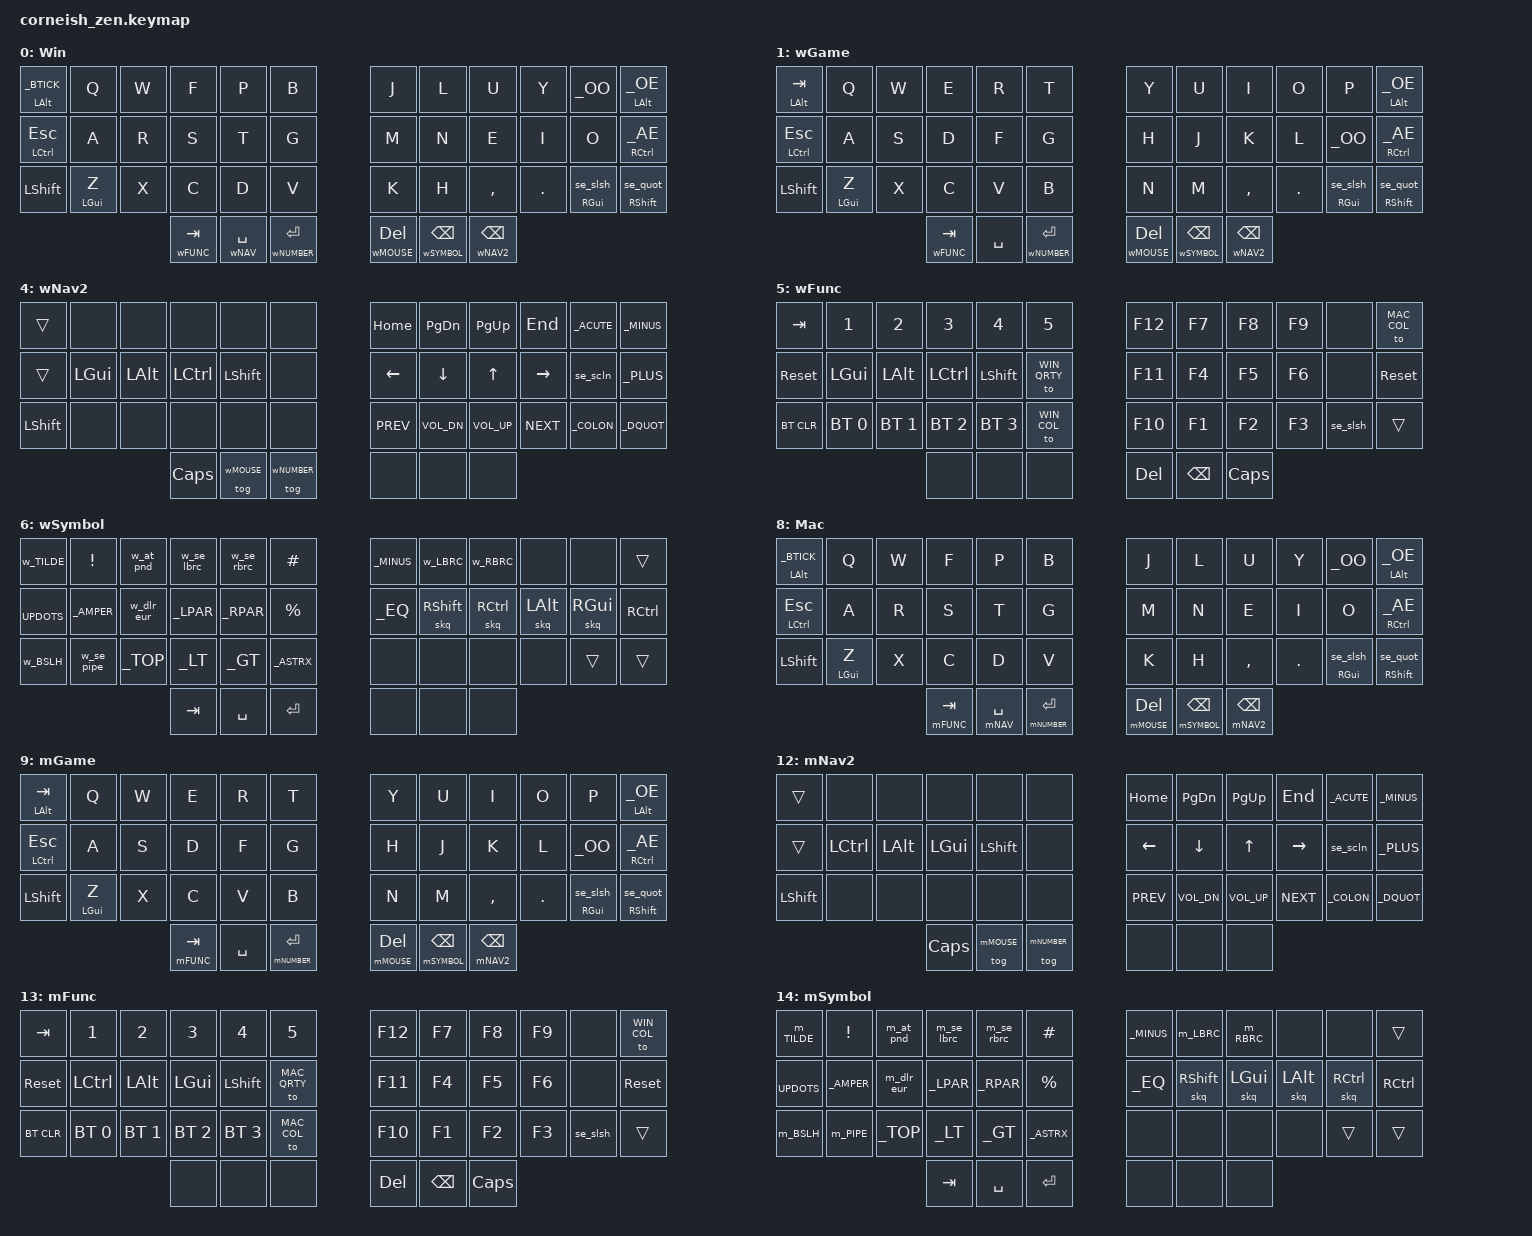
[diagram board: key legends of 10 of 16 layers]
#include <behaviors.dtsi>
#include <dt-bindings/zmk/keys.h>
#include <dt-bindings/zmk/bt.h>

// Override default movement and scrolling max velocities
#define ZMK_POINTING_DEFAULT_MOVE_VAL 1500  // default: 600
#define ZMK_POINTING_DEFAULT_SCRL_VAL 20    // default: 10
#include <dt-bindings/zmk/pointing.h>

// Layers for Windows
#define WIN_COL   0
#define WIN_QRTY  1
#define wNUMBER   2
#define wNAV      3
#define wNAV2     4
#define wFUNC     5
#define wSYMBOL   6
#define wMOUSE    7

// Layers for Mac
#define MAC_COL   8
#define MAC_QRTY  9
#define mNUMBER  10
#define mNAV     11
#define mNAV2    12
#define mFUNC    13
#define mSYMBOL  14
#define mMOUSE   15

// Home row mods macros for Windows
#define wHRML1(k1,k2) &l_ht LC(LGUI) k1   &l_ht LS(LALT) k2
#define wHRML2(k1,k2,k3,k4,k5,k6) &l_ht LCTRL k1   &l_ht LGUI k2   &l_ht LALT k3   &l_ht LCTRL k4   &l_ht LSHIFT k5   &l_ht LC(LS(LALT)) k6
#define wHRML3(k1,k2,k3,k4) &l_ht LA(LGUI) k1   &l_ht LC(LALT) k2   &l_ht LS(LCTRL) k3   &l_ht LC(LS(LA(LGUI))) k4

#define wHRMR1(k1,k2) &r_ht RS(RALT) k1   &r_ht RC(RGUI) k2
#define wHRMR2(k1,k2,k3,k4) &r_ht RC(RS(RALT)) k1   &r_ht RSHIFT k2   &r_ht RCTRL k3   &r_ht LALT k4
#define wHRMR3(k1,k2,k3,k4) &r_ht RC(RS(RA(RGUI))) k1   &r_ht RS(RCTRL) k2   &r_ht RC(RALT) k3   &r_ht RA(RGUI) k4

// Home row mods macros for Mac
#define mHRML1(k1,k2) &l_ht LC(LGUI) k1   &l_ht LS(LALT) k2
#define mHRML2(k1,k2,k3,k4,k5,k6) &l_ht LGUI k1   &l_ht LCTRL k2   &l_ht LALT k3   &l_ht LGUI k4   &l_ht LSHIFT k5   &l_ht LC(LS(LALT)) k6
#define mHRML3(k1,k2,k3,k4) &l_ht LA(LCTRL) k1   &l_ht LG(LALT) k2   &l_ht LS(LGUI) k3   &l_ht LC(LS(LA(LGUI))) k4

#define mHRMR1(k1,k2) &r_ht RS(RALT) k1   &r_ht RC(RGUI) k2
#define mHRMR2(k1,k2,k3,k4) &r_ht RC(RS(RALT)) k1   &r_ht RSHIFT k2   &r_ht RGUI k3   &r_ht LALT k4
#define mHRMR3(k1,k2,k3,k4) &r_ht RC(RS(RA(RGUI))) k1   &r_ht RS(RGUI) k2   &r_ht RG(RALT) k3   &r_ht RA(RCTRL) k4

// Short commands macros for Windows
#define wSHRT1(k1,k2,k3) &kp LC(k1)   &kp LC(k2)   &kp LA(LC(k3))
#define wSHRT2(k1,k2,k3,k4,k5) &l_ht LCTRL LC(k1)   &l_ht LALT LC(k2)   &l_ht LGUI LC(k3)   &l_ht LSHIFT LC(k4)   &kp LC(k5)
#define wSHRT3(k1,k2,k3,k4,k5) &kp LC(k1)   &kp LC(k2)   &kp LC(k3)   &kp LC(k4)   &kp LC(k5)

// Short commands macros for Mac
#define mSHRT1(k1,k2,k3) &kp LG(k1)   &kp LG(k2)   &kp LA(LG(k3))
#define mSHRT2(k1,k2,k3,k4,k5) &l_ht LCTRL LG(k1)   &l_ht LALT LG(k2)   &l_ht LGUI LG(k3)   &l_ht LSHIFT LG(k4)   &kp LG(k5)
#define mSHRT3(k1,k2,k3,k4,k5) &kp LG(k1)   &kp LG(k2)   &kp LG(k3)   &kp LG(k4)   &kp LG(k5)

// Special Swedish character macro for Windows and Mac
#define _OE    LBKT                /* Å */
#define _AE    SQT                 /* Ä */
#define _OO    SEMI                /* Ö */
#define _AMPER CARET               /* & */
#define w_BSLH  RC(RA(MINUS))      /* \ Windows */
#define m_BSLH  LS(RA(N7))         /* \ Mac */
#define _LT    NON_US_BSLH         /* < */
#define _GT    LS(NON_US_BSLH)     /* > */
#define _ASTRX LS(NON_US_HASH)     /* * */
#define _UPDOTS RBKT               /* ¨ */
#define w_TILDE RC(RA(RBKT))       /* ~ Windows */
#define m_TILDE RA(RBKT)           /* ~ Mac */
#define _LPAR  LS(N8)              /* ( */
#define _RPAR  LS(N9)              /* ) */
#define _TOP   RBRC                /* ^ */
#define _EQ    RPAR                /* = */
#define _UNDER LS(FSLH)            /* _ */
#define _MINUS FSLH                /* - */
#define _PLUS  MINUS               /* + */
#define _SQUOT NON_US_HASH         /* ' */
#define _DQUOT LS(N2)              /* " */
#define _SEMIC LS(COMMA)           /* ; */
#define _COLON LS(DOT)             /* : */
#define _FSLH  KP_DIVIDE           /* / */
#define _QMARK LS(MINUS)           /* ? */
#define w_LBKT  RC(RA(N8))         /* [ Windows */
#define m_LBKT  RA(N8)             /* [ Mac */
#define w_LBRC  RC(RA(N7))         /* { Windows */
#define m_LBRC  LS(RA(N8))         /* { Mac */
#define w_RBKT  RC(RA(N9))         /* ] Windows */
#define m_RBKT  RA(N9)             /* ] Mac */
#define w_RBRC  RC(RA(N0))         /* } Windows */
#define m_RBRC  LS(RA(N9))         /* } Mac */
#define w_PIPE  RC(RA(NUBS))       /* | Windows */
#define m_PIPE  RA(N7)             /* | Mac */
#define w_AT    RC(RA(N2))         /* @ Windows */
#define m_AT    RA(N2)             /* @ Mac */
#define w_DOLAR RC(RA(N4))         /* $ Windows */
#define m_DOLAR RA(N4)             /* $ Mac */
#define w_EURO  RC(RA(N5))         /* € Windows */
#define m_EURO  LS(N4)             /* € Mac */
#define w_POUND RC(RA(N3))         /* £ Windows */
#define m_POUND RA(N3)             /* £ Mac */
#define w_MICRO RC(RA(M))          /* µ Windows*/ 
#define m_MICRO RA(Y)              /* µ Mac*/ 
#define _PARGH GRAVE               /* § */
#define _HALF  LS(GRAVE)           /* ½  Windows, ° Mac*/
#define _ACUTE EQUAL               /* ´ */
#define _BTICK LS(EQUAL)           /* ` */

&mmv {
    // x-input-code = <INPUT_REL_X>;
    // y-input-code = <INPUT_REL_Y>;
    time-to-max-speed-ms = <300>;
    acceleration-exponent = <1>;
};


&msc {
    // x-input-code = <INPUT_REL_HWHEEL>;
    // y-input-code = <INPUT_REL_WHEEL>;
    time-to-max-speed-ms = <300>;
    acceleration-exponent = <1>;
};

/ {
     chosen {
          zmk,matrix_transform = &default_transform;
          //zmk,matrix_transform = &five_column_transform;
     };
};

/ {
     behaviors {
          r_ht: right_hold_tap {
               compatible = "zmk,behavior-hold-tap";
               #binding-cells = <2>;
               flavor = "tap-preferred";
               tapping-term-ms = <175>;
               quick-tap-ms = <200>;
               require-prior-idle-ms = <125>;
               bindings = <&kp>, <&kp>;
               hold-trigger-key-positions = <
                    0  1  2  3  4  5 
                   12 13 14 15 16 17
                   24 25 26 27 28 29
                   36 37 38
               >;
          };
          l_ht: left_hold_tap {
               compatible = "zmk,behavior-hold-tap";
               #binding-cells = <2>;
               flavor = "tap-preferred";
               tapping-term-ms = <175>;
               quick-tap-ms = <200>;
               require-prior-idle-ms = <125>;
               bindings = <&kp>, <&kp>;
               hold-trigger-key-positions = <
                    6  7  8  9 10 11
                   18 19 20 21 22 23
                   30 31 32 33 34 35
                38 39 40 41
               >;
          };
          // modifify toggle for left hand behavior
          ht_tog: mod_tog {
               compatible = "zmk,behavior-hold-tap";
               label = "MOD_TOG";
               #binding-cells = <2>;
               flavor = "tap-preferred";
               tapping-term-ms = <175>;
               quick-tap-ms = <200>;
               require-prior-idle-ms = <125>;
               bindings = <&kp>, <&tog>;
               hold-trigger-key-positions = <
                     6  7  8  9 10 11
                    18 19 20 21 22 23
                    30 31 32 33 34 35
                 38 39 40 41
               >;
          };
          skq: sticky_key_quick_release {
               compatible = "zmk,behavior-sticky-key";
               #binding-cells = <1>;
               bindings = <&kp>;
               release-after-ms = <5000>;
               quick-release; // deactivate the sticky key on the next key being pressed, as opposed to released
               ignore-modifiers; // ensures sticky key modifier will get combined in chain, callum-style mods 
          };
          r_quot: right_side_quote {
               compatible = "zmk,behavior-hold-tap";
               #binding-cells = <2>;
               flavor = "tap-preferred";
               tapping-term-ms = <175>;
               quick-tap-ms = <200>;
               require-prior-idle-ms = <125>; 
               bindings = <&kp>, <&se_quot>; /* necessary special case because _DQUOT is alias for LS(N2) */
               hold-trigger-key-positions = <
                    0  1  2  3  4  5 
                   12 13 14 15 16 17
                   24 25 26 27 28 29
                   36 37 38
               >;
          };
          se_quot: single_quote_shift_double_quote {            
               compatible = "zmk,behavior-mod-morph";            
               #binding-cells = <0>;
               bindings = <&kp _SQUOT>, <&kp _DQUOT>; /* ' " */
               mods = <(MOD_LSFT|MOD_RSFT)>;
          };
          se_scln: semi_colon_shift_colon {            
               compatible = "zmk,behavior-mod-morph";            
               #binding-cells = <0>;
               bindings = <&kp _SEMIC>, <&kp _COLON>; /* ; : */
               mods = <(MOD_LSFT|MOD_RSFT)>;
          };
          r_slsh: right_side_slash_question {
              compatible = "zmk,behavior-hold-tap";
              #binding-cells = <2>;
              flavor = "tap-preferred";
              tapping-term-ms = <175>;
              quick-tap-ms = <200>;
              require-prior-idle-ms = <125>; 
              bindings = <&kp>, <&se_slsh>; /* necessary special case because _QMARK is alias for LS(MINUS) */
              hold-trigger-key-positions = <
                   0  1  2  3  4  5 
                  12 13 14 15 16 17
                  24 25 26 27 28 29
                  36 37 38
              >;
          };
          se_slsh: slash_shift_question {            
               compatible = "zmk,behavior-mod-morph";            
               #binding-cells = <0>;
               bindings = <&kp _FSLH>, <&kp _QMARK>; /* / ? */
               mods = <(MOD_LSFT|MOD_RSFT)>;
          };
          w_se_pipe: w_se_pipe {            
               compatible = "zmk,behavior-mod-morph";            
               #binding-cells = <0>;
               bindings = <&kp w_PIPE>, <&kp w_BSLH>; /* [ { Windows */
               mods = <(MOD_LSFT|MOD_RSFT)>;
          };
          w_se_lbrc: w_se_left_bracket {            
               compatible = "zmk,behavior-mod-morph";            
               #binding-cells = <0>;
               bindings = <&kp w_LBKT>, <&kp w_LBRC>; /* [ { Windows */
               mods = <(MOD_LSFT|MOD_RSFT)>;
          };
          m_se_lbrc: m_se_left_bracket {            
               compatible = "zmk,behavior-mod-morph";            
               #binding-cells = <0>;
               bindings = <&kp m_LBKT>, <&kp m_LBRC>; /* [ { Mac */
               mods = <(MOD_LSFT|MOD_RSFT)>;
          };
          w_se_rbrc: w_se_right_bracket {            
               compatible = "zmk,behavior-mod-morph";            
               #binding-cells = <0>;
               bindings = <&kp w_RBKT>, <&kp w_RBRC>; /* ] } Windows */
               mods = <(MOD_LSFT|MOD_RSFT)>;
          };
          m_se_rbrc: m_se_right_bracket {            
               compatible = "zmk,behavior-mod-morph";            
               #binding-cells = <0>;
               bindings = <&kp m_RBKT>, <&kp m_RBRC>; /* ] } Mac */
               mods = <(MOD_LSFT|MOD_RSFT)>;
          };
          w_at_pnd: w_at_shift_pound {            
               compatible = "zmk,behavior-mod-morph";            
               #binding-cells = <0>;
               bindings = <&kp w_AT>, <&kp w_POUND>; /* @ £  Windows */
               mods = <(MOD_LSFT|MOD_RSFT)>;
               keep-mods = <(MOD_LSFT|MOD_RSFT)>; // Keep the shift modifier active
          };
          m_at_pnd: m_at_shift_pound {            
               compatible = "zmk,behavior-mod-morph";            
               #binding-cells = <0>;
               bindings = <&kp m_AT>, <&pound_fix>; /* @ £ Mac */
               mods = <(MOD_LSFT|MOD_RSFT)>;
               keep-mods = <(MOD_LSFT|MOD_RSFT)>; // Important: Keep track of shift state
          };
          /* macro that explicitly releases shift modifiers, then taps the £ such that it doesn't result in ¥ */
          pound_fix: pound_fix {
               compatible = "zmk,behavior-macro";
               #binding-cells = <0>;
               wait-ms = <10>;
               tap-ms = <10>;
               bindings = 
                  <&macro_release &kp LSHFT &kp RSHFT>,  // Release shifts
                  <&macro_wait_time 10>,                 // Short pause
                  <&macro_tap &kp m_POUND>,              // Tap the Alt+3 for £
                  <&macro_wait_time 10>,                 // Short pause
                  <&macro_tap &sk 0>;                    // Reset sticky keys state
        };
          w_dlr_eur: w_dollar_shift_eur {
               compatible = "zmk,behavior-mod-morph";            
               #binding-cells = <0>;
               bindings = <&kp w_DOLAR>, <&kp w_EURO>; /* $ € Windows */
               mods = <(MOD_LSFT|MOD_RSFT)>;
          };
          m_dlr_eur: m_dollar_shift_eur {
               compatible = "zmk,behavior-mod-morph";            
               #binding-cells = <0>;
               bindings = <&kp m_DOLAR>, <&kp m_EURO>; /* $ € Mac */
               mods = <(MOD_LSFT|MOD_RSFT)>;
          };
     };

     keymap {
          compatible = "zmk,keymap";

          w_colemak_layer {
               display-name = "Win";
               bindings = <
// -------------------------------------------------------------------------------     -------------------------------------------------------------------------------
// | `  ALT     | Q          | W          | F          | P          | B          |     | J          | L          | U          | Y          | Ö          | Å  ALT     |
&l_ht LALT _BTICK   &kp Q      &kp W        &kp F        &kp P        &kp B              &kp J        &kp L        &kp U        &kp Y        &kp _OO    &r_ht LALT _OE
// -------------------------------------------------------------------------------     -------------------------------------------------------------------------------
// | ESC  CTRL  | A          | R          | S          | T          | G          |     | M          | N          | E          | I          | O          | Ä  CTRL    |
&l_ht LCTRL ESC   &kp A        &kp R        &kp S        &kp T        &kp G              &kp M        &kp N        &kp E        &kp I        &kp O      &r_ht RCTRL _AE
// -------------------------------------------------------------------------------     -------------------------------------------------------------------------------
// | SHIFT      | Z  GUI     | X          | C          | D          | V          |     | K          | H          | ,          | .          | / ?  GUI   | ' " SHIFT  |
  &kp LSHIFT    &l_ht LGUI Z   &kp X        &kp C        &kp D        &kp V              &kp K        &kp H        &kp COMMA    &kp DOT  &r_slsh RGUI 0  &r_quot RSHIFT 0
// -------------------------------------------------------------------------------     -------------------------------------------------------------------------------
//                      | TAB FUNC         | SPACE NAV        | ENTER NUMBER     |     | DEL MOUSE        | BSP SYMBOL       | BSP NAV2         |
                          &lt wFUNC TAB      &lt wNAV SPACE     &lt wNUMBER RET          &lt wMOUSE DEL     &lt wSYMBOL BSPC   &lt wNAV2 BSPC
//                      ----------------------------------------------------------     ----------------------------------------------------------
               >;
          };

          w_gaming_layer {
               display-name = "wGame";
               bindings = <
// -------------------------------------------------------------------------------     -------------------------------------------------------------------------------
// | TAB  ALT   | Q          | W          | E          | R          | T          |     | Y          | U          | I          | O          | P          | Å  ALT     |
&l_ht LALT TAB    &kp Q        &kp W        &kp E        &kp R        &kp T              &kp Y        &kp U        &kp I        &kp O        &kp P      &r_ht LALT _OE    
// -------------------------------------------------------------------------------     -------------------------------------------------------------------------------
// | ESC  CTRL  | A          | S          | D          | F          | G          |     | H          | J          | K          | L          | Ö          | Ä  CTRL    |
 &l_ht LCTRL ESC  &kp A        &kp S        &kp D        &kp F        &kp G              &kp H        &kp J        &kp K        &kp L        &kp _OO    &r_ht RCTRL _AE
// -------------------------------------------------------------------------------     -------------------------------------------------------------------------------
// | SHIFT      | Z  GUI     | X          | C          | V          | B          |     | N          | M          | ,          | .          | / ?  GUI   | ' " SHIFT  |
  &kp LSHIFT    &l_ht LGUI Z   &kp X        &kp C        &kp V        &kp B              &kp N        &kp M        &kp COMMA    &kp DOT  &r_slsh RGUI 0  &r_quot RSHIFT 0
// -------------------------------------------------------------------------------     -------------------------------------------------------------------------------
//                      | TAB FUNC         | SPACE            | ENTER NUMBER     |     | DEL MOUSE        | BSP SYMBOL       | BSP NAV2         |
                          &lt wFUNC TAB      &kp SPACE          &lt wNUMBER RET          &lt wMOUSE DEL     &lt wSYMBOL BSPC   &lt wNAV2 BSPC
//                      ----------------------------------------------------------     ----------------------------------------------------------
               >;
          };

          w_number_layer {
               display-name = "wNumber";
               bindings = <
// -------------------------------------------------------------------------------     -------------------------------------------------------------------------------
// | TAB        | 1          | 2          | 3          | 4          | 5          |     | 6          | 7          | 8          | 9          | 0          | BSP        |
     &kp TAB      &kp N1       &kp N2       &kp N3       &kp N4       &kp N5             &kp N6       &kp N7       &kp N8       &kp N9       &kp N0       &kp BSPC
// -------------------------------------------------------------------------------     -------------------------------------------------------------------------------
// |TOGGLE LCTRL| LGUI       | LALT       | LCTRL      | LSHFT      |            |     | ,          | 4          | 5          | 6          | ; :        | + ?        |
&ht_tog LCTRL wNUMBER  &kp LGUI  &kp LALT   &kp LCTRL    &kp LSHIFT   &none              &kp COMMA    &kp N4       &kp N5       &kp N6       &se_scln     &kp _PLUS
// -------------------------------------------------------------------------------     -------------------------------------------------------------------------------
// | SHIFT      | UNDO       | CUT        | COPY       | CTRL + D   | PASTE      |     | .          | 1          | 2          | 3          | :          | "          |
     &kp LSHIFT   wSHRT3(Z,         X,           C,           D,           V)            &kp DOT      &kp N1       &kp N2       &kp N3       &kp _COLON   &kp _DQUOT
// -------------------------------------------------------------------------------     -------------------------------------------------------------------------------
//                      | FUNC             | NAV SPACE        | ENTER            |     | =                | 0 SYM            | - _ NAV2         |
                          &mo wFUNC          &lt wNAV SPACE     &kp RET                  &kp _EQ            &lt wSYMBOL N0     &lt wNAV2 _MINUS  
//                      ----------------------------------------------------------     ----------------------------------------------------------
               >;
          };

          w_navigation_layer {
               display-name = "wNav";
               bindings = <
// -------------------------------------------------------------------------------     -------------------------------------------------------------------------------
// |            | !          | @ £        | FIND       | CTRL + P   | GO-TO IDEA |     | HOME       | PAGE DOWN  | PAGE UP    | END        | ´ `        | - _        |
     &trans       &kp EXCL     &w_at_pnd     wSHRT1(F,         P,           B)           &kp HOME     &kp PG_DN    &kp PG_UP    &kp END      &kp _ACUTE   &kp _MINUS
// -------------------------------------------------------------------------------     -------------------------------------------------------------------------------
// |            | LGUI 1 shot| LALT 1 shot|LCTRL 1 shot|LSHFT 1 shot| CTRL + G   |     | LEFT       | DOWN       | UP         | RIGTH      | ; :        | + ?        |
     &trans       &skq LGUI    &skq LALT   &skq LCTRL   &skq LSHIFT   &kp LC(G)          &kp LEFT     &kp DOWN     &kp UP       &kp RIGHT    &se_scln     &kp _PLUS
// -------------------------------------------------------------------------------     -------------------------------------------------------------------------------
// | SHIFT      | UNDO       | CUT        | COPY       | CTRL + D   | PASTE      |     | <<         | vol-       | vol+       | >>         | :          | "          |
     &kp LSHIFT   wSHRT3(Z,         X,           C,           D,           V)            &kp C_PREV   &kp C_VOL_DN &kp C_VOL_UP &kp C_NEXT   &kp _COLON   &kp _DQUOT
// -------------------------------------------------------------------------------     -------------------------------------------------------------------------------
//                      |                  |                  |                  |     | =                | _                | - _              |
                          &none              &none              &none                    &kp _EQ            &kp _UNDER         &kp _MINUS
//                      ----------------------------------------------------------     ----------------------------------------------------------
               >;
          };

          w_navigation_2_layer {
               display-name = "wNav2";
               bindings = <
// -------------------------------------------------------------------------------     -------------------------------------------------------------------------------
// |            |            |            |            |            |            |     | HOME       | PAGE DOWN  | PAGE UP    | END        | ´ `        | - _        |
     &trans       &none        &none        &none        &none        &none              &kp HOME     &kp PG_DN    &kp PG_UP    &kp END      &kp _ACUTE   &kp _MINUS
// -------------------------------------------------------------------------------     -------------------------------------------------------------------------------
// |            | LGUI       | LALT       | LCTRL      | LSHFT      |            |     | LEFT       | DOWN       | UP         | RIGTH      | ; :        | + ?        |
     &trans       &kp LGUI     &kp LALT     &kp LCTRL    &kp LSHIFT   &none              &kp LEFT     &kp DOWN     &kp UP       &kp RIGHT    &se_scln     &kp _PLUS
// -------------------------------------------------------------------------------     -------------------------------------------------------------------------------
// | SHIFT      |            |            |            |            |            |     | <<         | vol-       | vol+       | >>         | :          | "          |
     &kp LSHIFT   &none        &none        &none        &none        &none              &kp C_PREV   &kp C_VOL_DN &kp C_VOL_UP &kp C_NEXT   &kp _COLON   &kp _DQUOT
// -------------------------------------------------------------------------------     -------------------------------------------------------------------------------
//                      | CAPS LOCK        | TOGGLE MOUSE     | TOGGLE NUMBER    |     |                  |                  |                  |
                          &kp CAPS           &tog wMOUSE        &tog wNUMBER              &none              &none              &none
//                      ----------------------------------------------------------     ----------------------------------------------------------
               >;
          };

          w_function_layer {
               display-name = "wFunc";
               bindings = <
// -------------------------------------------------------------------------------     -------------------------------------------------------------------------------
// | TAB        | 1          | 2          | 3          | 4          | 5          |     | F12        | F7         | F8         | F9         |            | MAC LAYER  |
     &kp TAB      &kp N1       &kp N2       &kp N3       &kp N4       &kp N5             &kp F12      &kp F7       &kp F8       &kp F9       &none        &to MAC_COL
// -------------------------------------------------------------------------------     -------------------------------------------------------------------------------
// | reset LEFT | LGUI       | LALT       | LCTRL      | LSHFT      | GAMING     |     | F11        | F4         | F5         | F6         |            | reset RIGHT|
     &sys_reset   &kp LGUI     &kp LALT     &kp LCTRL    &kp LSHIFT  &to WIN_QRTY        &kp F11      &kp F4       &kp F5       &kp F6       &none        &sys_reset 
// -------------------------------------------------------------------------------     -------------------------------------------------------------------------------
// | BTCLR      | BT1        | BT2        | BT3        | BT4        | COLEMAK    |     | F10        | F1         | F2         | F3         | / ?        |            |
     &bt BT_CLR  &bt BT_SEL 0 &bt BT_SEL 1 &bt BT_SEL 2 &bt BT_SEL 3  &to WIN_COL        &kp F10      &kp F1       &kp F2       &kp F3       &se_slsh     &trans 
// -------------------------------------------------------------------------------     -------------------------------------------------------------------------------
//                      |                  |                  |                  |     | DEL              | BSPC             | CAPS             |
                          &none              &none              &none                    &kp DEL            &kp BSPC           &kp CAPS
//                      ----------------------------------------------------------     ----------------------------------------------------------
               >;
          };

          w_symbol_layer {
               display-name = "wSymbol";
               bindings = <
// -------------------------------------------------------------------------------     -------------------------------------------------------------------------------
// | ~          | !          | @ £        | [ {        | ] }        | #          |     | -          | {          | }          |            |            |            |
     &kp w_TILDE  &kp EXCL     &w_at_pnd    &w_se_lbrc   &w_se_rbrc   &kp HASH           &kp _MINUS   &kp w_LBRC   &kp w_RBRC   &none        &none        &trans
// -------------------------------------------------------------------------------     -------------------------------------------------------------------------------
// | ¨ ^        | &          | $ €        | (          | )          | %          |     | =          |RSHFT 1 shot|RCTRL 1 shot| LALT 1 shot|RGUI 1 shot | RCTRL      |
     &kp _UPDOTS  &kp _AMPER   &w_dlr_eur   &kp _LPAR    &kp _RPAR    &kp PRCNT          &kp _EQ      &skq RSHIFT  &skq RCTRL  &skq LALT    &skq RGUI     &kp RCTRL
// -------------------------------------------------------------------------------     -------------------------------------------------------------------------------
// | \          | "|" \      | ^          | <          | >          | *          |     |            |            |            |            |            |            |
     &kp w_BSLH   &w_se_pipe   &kp _TOP     &kp _LT      &kp _GT      &kp _ASTRX         &none        &none        &none        &none        &trans       &trans
// -------------------------------------------------------------------------------     -------------------------------------------------------------------------------
//                      | TAB              | SPACE            | ENTER            |     |                  |                  |                  |  
                          &kp TAB            &kp SPACE          &kp RET                  &none              &none              &none
//                      ----------------------------------------------------------     ----------------------------------------------------------  
               >;
          };

          w_mouse_layer {
               display-name = "wMouse";
               bindings = <
// -------------------------------------------------------------------------------     -------------------------------------------------------------------------------
// | TAB        |            | SCROLL LEFT| MOUSE UP   |SCROLL RIGHT| SCROLL UP  |     |WEB TAB LEFT|WEB TAB BACK|WEB TAB FRWD|WEB TAB RGHT|            |            |
     &kp TAB      &none   &msc SCRL_LEFT  &mmv MOVE_UP  &msc SCRL_RIGHT  &msc SCRL_UP  &kp LS(LC(TAB))  &kp LA(LEFT)  &kp LA(RIGHT)  &kp LC(TAB)  &none   &trans
// -------------------------------------------------------------------------------     -------------------------------------------------------------------------------
// |TOGGLE LCTRL| SCROLL LEFT| MOUSE LEFT | MOUSE DOWN | MOUSE RIGHT|SCROLL DOWN |     | LEFT  mod  | DOWN mod   | UP mod     | RIGHT mod  | LGUI       | LCTRL      |
&ht_tog LCTRL wMOUSE  &msc &none  &mmv MOVE_LEFT  &mmv MOVE_DOWN  &mmv MOVE_RIGHT  &msc SCRL_DOWN  wHRMR2(LEFT,  DOWN,  UP,  RIGHT)          &kp LGUI     &kp LCTRL    
// -------------------------------------------------------------------------------     -------------------------------------------------------------------------------
// | SHIFT      | UNDO       | CUT        | COPY       | CTRL + D   | PASTE      |     |MIDDLE CLICK| LEFT CLICK | RIGHT CLICK|            |            |            |
     &kp LSHIFT   wSHRT3(Z,         X,           C,           D,           V)            &mkp MCLK    &mkp LCLK    &mkp RCLK    &none        &trans       &trans 
// -------------------------------------------------------------------------------     -------------------------------------------------------------------------------
//                      |MIDDLE CLICK      | LEFT CLICK       | RIGHT CLICK      |     |                  |                  |                  |
                          &mkp MCLK          &mkp LCLK          &mkp RCLK                &none              &none              &none
//                      ----------------------------------------------------------     ----------------------------------------------------------
               >;
          };

          m_colemak_layer {
               display-name = "Mac";
               bindings = <
// -------------------------------------------------------------------------------     -------------------------------------------------------------------------------
// | `  ALT     | Q          | W          | F          | P          | B          |     | J          | L          | U          | Y          | Ö          | Å  ALT     |
&l_ht LALT _BTICK   &kp Q      &kp W        &kp F        &kp P        &kp B              &kp J        &kp L        &kp U        &kp Y        &kp _OO    &r_ht LALT _OE
// -------------------------------------------------------------------------------     -------------------------------------------------------------------------------
// | ESC  CTRL  | A          | R          | S          | T          | G          |     | M          | N          | E          | I          | O          | Ä  CTRL    |
&l_ht LCTRL ESC   &kp A        &kp R        &kp S        &kp T        &kp G              &kp M        &kp N        &kp E        &kp I        &kp O      &r_ht RCTRL _AE
// -------------------------------------------------------------------------------     -------------------------------------------------------------------------------
// | SHIFT      | Z  GUI     | X          | C          | D          | V          |     | K          | H          | ,          | .          | / ?  GUI   | ' " SHIFT  |
  &kp LSHIFT   &l_ht LGUI Z    &kp X        &kp C        &kp D        &kp V              &kp K        &kp H        &kp COMMA    &kp DOT  &r_slsh RGUI 0  &r_quot RSHIFT 0
// -------------------------------------------------------------------------------     -------------------------------------------------------------------------------
//                      | TAB FUNC         | SPACE NAV        | ENTER NUMBER     |     | DEL MOUSE        | BSP SYMBOL       | BSP NAV2         |
                          &lt mFUNC TAB      &lt mNAV SPACE     &lt mNUMBER RET          &lt mMOUSE DEL     &lt mSYMBOL BSPC   &lt mNAV2 BSPC
//                      ----------------------------------------------------------     ----------------------------------------------------------
               >;
          };

          m_gaming_layer {
               display-name = "mGame";
               bindings = <
// -------------------------------------------------------------------------------     -------------------------------------------------------------------------------
// | TAB  ALT   | Q          | W          | E          | R          | T          |     | Y          | U          | I          | O          | P          | Å  ALT     |
&l_ht LALT TAB    &kp Q        &kp W        &kp E        &kp R        &kp T              &kp Y        &kp U        &kp I        &kp O        &kp P      &r_ht LALT _OE    
// -------------------------------------------------------------------------------     -------------------------------------------------------------------------------
// | ESC  LCTRL | A          | S          | D          | F          | G          |     | H          | J          | K          | L          | Ö          | Ä  RCTRL    |
 &l_ht LCTRL ESC  &kp A        &kp S        &kp D        &kp F        &kp G              &kp H        &kp J        &kp K        &kp L        &kp _OO    &r_ht RCTRL _AE
// -------------------------------------------------------------------------------     -------------------------------------------------------------------------------
// | SHIFT      | Z  GUI     | X          | C          | V          | B          |     | N          | M          | ,          | .          | / ?  GUI   | ' "  SHIFT |
  &kp LSHIFT   &l_ht LGUI Z    &kp X        &kp C        &kp V        &kp B              &kp N        &kp M        &kp COMMA    &kp DOT  &r_slsh RGUI 0  &r_quot RSHIFT 0
// -------------------------------------------------------------------------------     -------------------------------------------------------------------------------
//                      | TAB FUNC         | SPACE            | ENTER NUMBER     |     | DEL MOUSE        | BSP SYMBOL       | BSP NAV2         |
                          &lt mFUNC TAB      &kp SPACE          &lt mNUMBER RET          &lt mMOUSE DEL     &lt mSYMBOL BSPC   &lt mNAV2 BSPC
//                      ----------------------------------------------------------     ----------------------------------------------------------
               >;
          };

          m_number_layer {
               display-name = "mNumber";
               bindings = <
// -------------------------------------------------------------------------------     -------------------------------------------------------------------------------
// | TAB        | 1          | 2          | 3          | 4          | 5          |     | 6          | 7          | 8          | 9          | 0          | BSP        |
     &kp TAB      &kp N1       &kp N2       &kp N3       &kp N4       &kp N5             &kp N6       &kp N7       &kp N8       &kp N9       &kp N0       &kp BSPC 
// -------------------------------------------------------------------------------     -------------------------------------------------------------------------------
// |TOGGLE LCTRL| LCTRL      | LALT       | LGUI       | LSHFT      |            |     | ,          | 4          | 5          | 6          | ; :        | + ?        |
&ht_tog LCTRL mNUMBER  &kp LCTRL  &kp LALT  &kp LGUI     &kp LSHIFT   &none              &kp COMMA    &kp N4       &kp N5       &kp N6       &se_scln     &kp _PLUS
// -------------------------------------------------------------------------------     -------------------------------------------------------------------------------
// | SHIFT      | UNDO       | CUT        | COPY       | CTRL + D   | PASTE      |     | .          | 1          | 2          | 3          | :          | "          |
     &kp LSHIFT   mSHRT3(Z,         X,           C,           D,           V)            &kp DOT      &kp N1       &kp N2       &kp N3       &kp _COLON   &kp _DQUOT
// -------------------------------------------------------------------------------     -------------------------------------------------------------------------------
//                      | FUNC             | NAV SPACE        | ENTER            |     | =                | 0 SYM            | - _ NAV2         |
                          &mo mFUNC          &lt mNAV SPACE     &kp RET                  &kp _EQ            &lt mSYMBOL N0     &lt mNAV2 _MINUS 
//                      ----------------------------------------------------------     ----------------------------------------------------------
               >;
          };

          m_navigation_layer {
               display-name = "mNav";
               bindings = <
// -------------------------------------------------------------------------------     -------------------------------------------------------------------------------
// |            | !          | @ £        | FIND       |  COM + P   | GO-TO IDEA |     | HOME       | PAGE DOWN  | PAGE UP    | END        | ´ `        | - _        |
     &trans       &kp EXCL     &m_at_pnd    mSHRT1(F,         P,           B)            &kp HOME     &kp PG_DN    &kp PG_UP    &kp END      &kp _ACUTE   &kp _MINUS
// -------------------------------------------------------------------------------     -------------------------------------------------------------------------------
// |            |LCTRL 1 shot| LALT 1 shot| LGUI 1 shot|LSHFT 1 shot| COM + G    |     | LEFT       | DOWN       | UP         | RIGTH      | ; :        | + ?        |
     &trans       &skq LCTRL   &skq LALT    &skq LGUI   &skq LSHIFT   &kp LG(G)          &kp LEFT     &kp DOWN     &kp UP       &kp RIGHT    &se_scln     &kp _PLUS 
// -------------------------------------------------------------------------------     -------------------------------------------------------------------------------
// | SHIFT      | UNDO       | CUT        | COPY       |  COM + D   | PASTE      |     | <<         | vol-       | vol+       | >>         | :          | "          |
     &kp LSHIFT   mSHRT3(Z,         X,           C,           D,           V)            &kp C_PREV   &kp C_VOL_DN &kp C_VOL_UP &kp C_NEXT   &kp _COLON   &kp _DQUOT
// -------------------------------------------------------------------------------     -------------------------------------------------------------------------------
//                      |                  |                  |                  |     | =                | _                | - _              |
                          &none              &none              &none                    &kp _EQ            &kp _UNDER         &kp _MINUS
//                      ----------------------------------------------------------     ----------------------------------------------------------
               >;
          };

          m_navigation_2_layer {
               display-name = "mNav2";
               bindings = <
// -------------------------------------------------------------------------------     -------------------------------------------------------------------------------
// |            |            |            |            |            |            |     | HOME       | PAGE DOWN  | PAGE UP    | END        | ´ `        | - _        |
     &trans       &none        &none        &none        &none        &none              &kp HOME     &kp PG_DN    &kp PG_UP    &kp END      &kp _ACUTE   &kp _MINUS
// -------------------------------------------------------------------------------     -------------------------------------------------------------------------------
// |            | LCTRL      | LALT       | LGUI       | LSHFT      |            |     | LEFT       | DOWN       | UP         | RIGTH      | ; :        | + ?        |
     &trans       &kp LCTRL    &kp LALT     &kp LGUI     &kp LSHIFT   &none              &kp LEFT     &kp DOWN     &kp UP       &kp RIGHT    &se_scln     &kp _PLUS
// -------------------------------------------------------------------------------     -------------------------------------------------------------------------------
// | SHIFT      |            |            |            |            |            |     | <<         | vol-       | vol+       | >>         | :          | "          |
     &kp LSHIFT   &none        &none        &none        &none        &none              &kp C_PREV   &kp C_VOL_DN &kp C_VOL_UP &kp C_NEXT   &kp _COLON   &kp _DQUOT
// -------------------------------------------------------------------------------     -------------------------------------------------------------------------------
//                      | CAPS LOCK        | TOGGLE MOUSE     | TOGGLE NUMBER    |     |                  |                  |                  |
                          &kp CAPS           &tog mMOUSE        &tog mNUMBER              &none              &none              &none
//                      ----------------------------------------------------------     ----------------------------------------------------------
               >;
          };

          m_function_layer {
               display-name = "mFunc";
               bindings = <
// -------------------------------------------------------------------------------     -------------------------------------------------------------------------------
// | TAB        | 1          | 2          | 3          | 4          | 5          |     | F12        | F7         | F8         | F9         |            | WIN LAYER  |
     &kp TAB      &kp N1       &kp N2       &kp N3       &kp N4       &kp N5             &kp F12      &kp F7       &kp F8       &kp F9       &none        &to WIN_COL 
// -------------------------------------------------------------------------------     -------------------------------------------------------------------------------
// | reset LEFT | LCTRL      | LALT       | LGUI       | LSHFT      | GAMING     |     | F11        | F4         | F5         | F6         |            | reset RIGHT|
     &sys_reset   &kp LCTRL    &kp LALT     &kp LGUI     &kp LSHIFT  &to MAC_QRTY        &kp F11      &kp F4       &kp F5       &kp F6       &none        &sys_reset 
// -------------------------------------------------------------------------------     -------------------------------------------------------------------------------
// | BTCLR      | BT1        | BT2        | BT3        | BT4        | COLEMAK    |     | F10        | F1         | F2         | F3         | / ?        |            |
     &bt BT_CLR  &bt BT_SEL 0 &bt BT_SEL 1 &bt BT_SEL 2 &bt BT_SEL 3  &to MAC_COL        &kp F10      &kp F1       &kp F2       &kp F3       &se_slsh     &trans 
// -------------------------------------------------------------------------------     -------------------------------------------------------------------------------
//                      |                  |                  |                  |     | DEL              | BSPC             | CAPS             |
                          &none              &none              &none                    &kp DEL            &kp BSPC           &kp CAPS
//                      ----------------------------------------------------------     ----------------------------------------------------------
               >;
          };

          m_symbol_layer {
               display-name = "mSymbol";
               bindings = <
// -------------------------------------------------------------------------------     -------------------------------------------------------------------------------
// | ~          | !          | @ £        | [ {        | ] }        | #          |     | -          | {          | }          |            |            |            |
     &kp m_TILDE  &kp EXCL     &m_at_pnd    &m_se_lbrc   &m_se_rbrc   &kp HASH           &kp _MINUS   &kp m_LBRC   &kp m_RBRC   &none        &none        &trans
// -------------------------------------------------------------------------------     -------------------------------------------------------------------------------
// | ¨ ^        | &          | $ €        | (          | )          | %          |     | =          |RSHFT 1 shot| LGUI 1 shot| LALT 1 shot|RCTRL 1 shot| RCTRL      |
     &kp _UPDOTS  &kp _AMPER   &m_dlr_eur   &kp _LPAR    &kp _RPAR    &kp PRCNT          &kp _EQ     &skq RSHIFT   &skq LGUI    &skq LALT    &skq RCTRL   &kp RCTRL
// -------------------------------------------------------------------------------     -------------------------------------------------------------------------------
// | \          | "|" \      | ^          | <          | >          | *          |     |            |            |            |            |            |            |
     &kp m_BSLH   &kp m_PIPE   &kp _TOP     &kp _LT      &kp _GT      &kp _ASTRX         &none        &none        &none        &none        &trans       &trans
// -------------------------------------------------------------------------------     -------------------------------------------------------------------------------
//                      | TAB              | SPACE            | ENTER            |     |                  |                  |                  |  
                          &kp TAB            &kp SPACE          &kp RET                  &none              &none              &none
//                      ----------------------------------------------------------     ----------------------------------------------------------  
               >;
          };

          m_mouse_layer {
               display-name = "mMouse";
               bindings = <
// -------------------------------------------------------------------------------     -------------------------------------------------------------------------------
// | TAB        |            | SCROLL LEFT| MOUSE UP   |SCROLL RIGHT| SCROLL UP  |     |WEB TAB LEFT|WEB TAB BACK|WEB TAB FRWD|WEB TAB RGHT|            |            |
     &kp TAB      &none  &msc SCRL_LEFT  &mmv MOVE_UP  &msc SCRL_RIGHT  &msc SCRL_UP    &kp LS(LC(TAB))  &kp LG(LEFT)  &kp LG(RIGHT)  &kp LC(TAB)  &none       &trans
// -------------------------------------------------------------------------------     -------------------------------------------------------------------------------
// |TOGGLE LCTRL|            | MOUSE LEFT | MOUSE DOWN | MOUSE RIGHT| SCROLL DOWN|     | LEFT  mod  | DOWN mod   | UP mod     | RIGHT mod  | LGUI       | LCTRL      |
&ht_tog LCTRL mMOUSE  &none  &mmv MOVE_LEFT  &mmv MOVE_DOWN  &mmv MOVE_RIGHT  &msc SCRL_DOWN            mHRMR2(LEFT,     DOWN,     UP,     RIGHT)     &kp LGUI     &kp LCTRL  
// -------------------------------------------------------------------------------     -------------------------------------------------------------------------------
// | SHIFT      | UNDO       | CUT        | COPY       |  COM + D   | PASTE      |     |MIDDLE CLICK| LEFT CLICK | RIGHT CLICK|            |            |            |
     &kp LSHIFT   mSHRT3(Z,         X,           C,           D,           V)            &mkp MCLK    &mkp LCLK    &mkp RCLK    &none        &trans       &trans
// -------------------------------------------------------------------------------     -------------------------------------------------------------------------------
//                      |MIDDLE CLICK      | LEFT CLICK       | RIGHT CLICK      |     |                  |                  |                  |
                          &mkp MCLK          &mkp LCLK          &mkp RCLK                &none              &none              &none
//                      ----------------------------------------------------------     ----------------------------------------------------------
               >;
          };

     };
};
